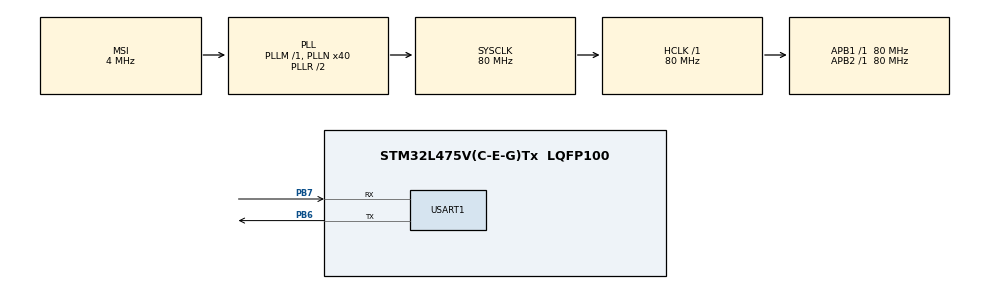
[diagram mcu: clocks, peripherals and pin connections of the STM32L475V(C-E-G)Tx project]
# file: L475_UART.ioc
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Mcu.Family=STM32L4
Mcu.Name=STM32L475V(C-E-G)Tx
Mcu.Package=LQFP100
NVIC.PriorityGroup=NVIC_PRIORITYGROUP_4
NVIC.USART1_IRQn=true\:0\:0\:false\:false\:true\:true\:true
PB6.Mode=Asynchronous
PB6.Signal=USART1_TX
PB7.Mode=Asynchronous
PB7.Signal=USART1_RX
ProjectManager.HeapSize=0x200
ProjectManager.StackSize=0x400
ProjectManager.TargetToolchain=STM32CubeIDE
RCC.ADCFreq_Value=48000000
RCC.AHBFreq_Value=80000000
RCC.APB1Freq_Value=80000000
RCC.APB1TimFreq_Value=80000000
RCC.APB2Freq_Value=80000000
RCC.APB2TimFreq_Value=80000000
RCC.CortexFreq_Value=80000000
RCC.HCLKFreq_Value=80000000
RCC.HSE_VALUE=8000000
RCC.HSI_VALUE=16000000
RCC.LSE_VALUE=32768
RCC.MSI_VALUE=4000000
RCC.PLLN=40
RCC.PLLSAI1N=24
RCC.SYSCLKFreq_VALUE=80000000
RCC.SYSCLKSource=RCC_SYSCLKSOURCE_PLLCLK
RCC.USBFreq_Value=48000000
RCC.VCOOutputFreq_Value=160000000
USART1.VirtualMode-Asynchronous=VM_ASYNC
board=B-L475E-IOT01A1

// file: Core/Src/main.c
/* USER CODE BEGIN Header */
/**
 ******************************************************************************
 * @file           : main.c
 * @brief          : Main program body
 ******************************************************************************
 * @attention
 *
 * <h2><center>&copy; Copyright (c) 2019 STMicroelectronics.
 * All rights reserved.</center></h2>
 *
 * This software component is licensed by ST under BSD 3-Clause license,
 * the "License"; You may not use this file except in compliance with the
 * License. You may obtain a copy of the License at:
 *                        opensource.org/licenses/BSD-3-Clause
 *
 ******************************************************************************
 */
/* USER CODE END Header */

#include "main.h"

/* USER CODE BEGIN Includes */
#include <stdio.h>
#include <string.h>

/* USER CODE END Includes */

UART_HandleTypeDef huart1;

void SystemClock_Config(void);
static void MX_GPIO_Init(void);
static void MX_USART1_UART_Init(void);

int main(void) {

	/* MCU Configuration--------------------------------------------------------*/

	/* Reset of all peripherals, Initializes the Flash interface and the Systick. */
	HAL_Init();

	/* Configure the system clock */
	SystemClock_Config();

	/* Initialize all configured peripherals */
	MX_GPIO_Init();
	MX_USART1_UART_Init();

	/* Infinite loop */
	/* USER CODE BEGIN WHILE */

	uint8_t tx_data[] = "Hello World\r\n";
	while (1) {
		/* USER CODE END WHILE */

		/* USER CODE BEGIN 3 */
		HAL_UART_Transmit(&huart1, tx_data, strlen((const char*)tx_data), 1000);
		HAL_Delay(1000);
	}
	/* USER CODE END 3 */
}

void SystemClock_Config(void) {
	RCC_OscInitTypeDef RCC_OscInitStruct = { 0 };
	RCC_ClkInitTypeDef RCC_ClkInitStruct = { 0 };
	RCC_PeriphCLKInitTypeDef PeriphClkInit = { 0 };

	/** Initializes the CPU, AHB and APB busses clocks
	 */
	RCC_OscInitStruct.OscillatorType = RCC_OSCILLATORTYPE_MSI;
	RCC_OscInitStruct.MSIState = RCC_MSI_ON;
	RCC_OscInitStruct.MSICalibrationValue = 0;
	RCC_OscInitStruct.MSIClockRange = RCC_MSIRANGE_6;
	RCC_OscInitStruct.PLL.PLLState = RCC_PLL_ON;
	RCC_OscInitStruct.PLL.PLLSource = RCC_PLLSOURCE_MSI;
	RCC_OscInitStruct.PLL.PLLM = 1;
	RCC_OscInitStruct.PLL.PLLN = 40;
	RCC_OscInitStruct.PLL.PLLP = RCC_PLLP_DIV7;
	RCC_OscInitStruct.PLL.PLLQ = RCC_PLLQ_DIV2;
	RCC_OscInitStruct.PLL.PLLR = RCC_PLLR_DIV2;
	if (HAL_RCC_OscConfig(&RCC_OscInitStruct) != HAL_OK) {
		Error_Handler();
	}
	/** Initializes the CPU, AHB and APB busses clocks
	 */
	RCC_ClkInitStruct.ClockType = RCC_CLOCKTYPE_HCLK | RCC_CLOCKTYPE_SYSCLK
			| RCC_CLOCKTYPE_PCLK1 | RCC_CLOCKTYPE_PCLK2;
	RCC_ClkInitStruct.SYSCLKSource = RCC_SYSCLKSOURCE_PLLCLK;
	RCC_ClkInitStruct.AHBCLKDivider = RCC_SYSCLK_DIV1;
	RCC_ClkInitStruct.APB1CLKDivider = RCC_HCLK_DIV1;
	RCC_ClkInitStruct.APB2CLKDivider = RCC_HCLK_DIV1;

	if (HAL_RCC_ClockConfig(&RCC_ClkInitStruct, FLASH_LATENCY_4) != HAL_OK) {
		Error_Handler();
	}
	PeriphClkInit.PeriphClockSelection = RCC_PERIPHCLK_USART1;
	PeriphClkInit.Usart1ClockSelection = RCC_USART1CLKSOURCE_PCLK2;
	if (HAL_RCCEx_PeriphCLKConfig(&PeriphClkInit) != HAL_OK) {
		Error_Handler();
	}
	/** Configure the main internal regulator output voltage
	 */
	if (HAL_PWREx_ControlVoltageScaling(PWR_REGULATOR_VOLTAGE_SCALE1)
			!= HAL_OK) {
		Error_Handler();
	}
}

static void MX_USART1_UART_Init(void) {

	huart1.Instance = USART1;
	huart1.Init.BaudRate = 115200;
	huart1.Init.WordLength = UART_WORDLENGTH_8B;
	huart1.Init.StopBits = UART_STOPBITS_1;
	huart1.Init.Parity = UART_PARITY_NONE;
	huart1.Init.Mode = UART_MODE_TX_RX;
	huart1.Init.HwFlowCtl = UART_HWCONTROL_NONE;
	huart1.Init.OverSampling = UART_OVERSAMPLING_16;
	huart1.Init.OneBitSampling = UART_ONE_BIT_SAMPLE_DISABLE;
	huart1.AdvancedInit.AdvFeatureInit = UART_ADVFEATURE_NO_INIT;
	if (HAL_UART_Init(&huart1) != HAL_OK) {
		Error_Handler();
	}

}

static void MX_GPIO_Init(void) {

	/* GPIO Ports Clock Enable */
	__HAL_RCC_GPIOB_CLK_ENABLE();

}

void Error_Handler(void) {
}

/************************ (C) COPYRIGHT STMicroelectronics *****END OF FILE****/
